AUTOSAR XML (schema 4-0-2)
package /AUTOSAR_ComM/SwcImplementations
  swc implementation ComM_Imp: programming-language=C, sw-version=5.4.0, vendor-id=6, behavior=ComM_Int
    code-descriptors:
      code ComM_Imp_Code: artifact-descriptors=autosar-engineering-object={short-label=Code, category=SWSRC}
    resource consumption ResourceConsumption_ResourceConsumption
package /AUTOSAR_ComM/SwComponentTypes
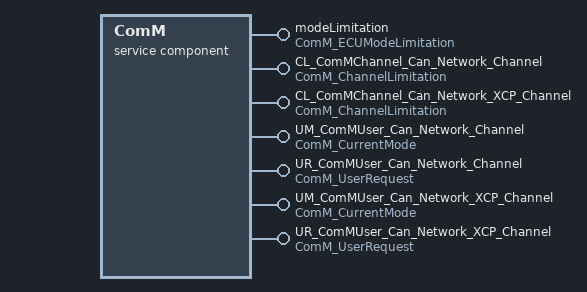
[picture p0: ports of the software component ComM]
  service sw component type ComM
    7 x provide port:
      modeLimitation: provided-interface=ComM_ECUModeLimitation
      CL_ComMChannel_Can_Network_Channel: provided-interface=ComM_ChannelLimitation
      CL_ComMChannel_Can_Network_XCP_Channel: provided-interface=ComM_ChannelLimitation
      UM_ComMUser_Can_Network_Channel: mode-switch-sender-com-spec{mode-group=currentMode, queue-length=1}, provided-interface=ComM_CurrentMode
      UR_ComMUser_Can_Network_Channel: server-com-spec{operation=RequestComMode, queue-length=5}, provided-interface=ComM_UserRequest
      UM_ComMUser_Can_Network_XCP_Channel: mode-switch-sender-com-spec{mode-group=currentMode, queue-length=1}, provided-interface=ComM_CurrentMode
      UR_ComMUser_Can_Network_XCP_Channel: server-com-spec{operation=RequestComMode, queue-length=5}, provided-interface=ComM_UserRequest
    behavior ComM_Int: data-type-mapping=ComMModeMapping, handle-termination-and-restart=CAN-BE-TERMINATED-AND-RESTARTED
      16 x operation invoked event:
        OIE_UR_ComMUser_Can_Network_Channel_RequestComMode: start-on-event=RequestComMode, operation=UR_ComMUser_Can_Network_Channel.RequestComMode
        OIE_UR_ComMUser_Can_Network_Channel_GetRequestedComMode: start-on-event=GetRequestedComMode, operation=UR_ComMUser_Can_Network_Channel.GetRequestedComMode
        OIE_UR_ComMUser_Can_Network_Channel_GetCurrentComMode: start-on-event=GetCurrentComMode, operation=UR_ComMUser_Can_Network_Channel.GetCurrentComMode
        OIE_UR_ComMUser_Can_Network_Channel_GetMaxComMode: start-on-event=GetMaxComMode, operation=UR_ComMUser_Can_Network_Channel.GetMaxComMode
        OIE_UR_ComMUser_Can_Network_XCP_Channel_RequestComMode: start-on-event=RequestComMode, operation=UR_ComMUser_Can_Network_XCP_Channel.RequestComMode
        OIE_UR_ComMUser_Can_Network_XCP_Channel_GetRequestedComMode: start-on-event=GetRequestedComMode, operation=UR_ComMUser_Can_Network_XCP_Channel.GetRequestedComMode
        OIE_UR_ComMUser_Can_Network_XCP_Channel_GetCurrentComMode: start-on-event=GetCurrentComMode, operation=UR_ComMUser_Can_Network_XCP_Channel.GetCurrentComMode
        OIE_UR_ComMUser_Can_Network_XCP_Channel_GetMaxComMode: start-on-event=GetMaxComMode, operation=UR_ComMUser_Can_Network_XCP_Channel.GetMaxComMode
        OIE_ML_LimitECUToNoComMode: start-on-event=LimitECUToNoComMode, operation=modeLimitation.LimitECUToNoComMode
        OIE_ML_ReadInhibitCounter: start-on-event=ReadInhibitCounter, operation=modeLimitation.ReadInhibitCounter
        OIE_ML_ResetInhibitCounter: start-on-event=ResetInhibitCounter, operation=modeLimitation.ResetInhibitCounter
        OIE_ML_SetECUGroupClassification: start-on-event=SetECUGroupClassification, operation=modeLimitation.SetECUGroupClassification
        OIE_CL_ComMChannel_Can_Network_Channel_LimitChannelToNoComMode: start-on-event=LimitChannelToNoComMode, operation=CL_ComMChannel_Can_Network_Channel.LimitChannelToNoComMode
        OIE_CL_ComMChannel_Can_Network_Channel_GetInhibitionStatus: start-on-event=GetInhibitionStatus, operation=CL_ComMChannel_Can_Network_Channel.GetInhibitionStatus
        OIE_CL_ComMChannel_Can_Network_XCP_Channel_LimitChannelToNoComMode: start-on-event=LimitChannelToNoComMode, operation=CL_ComMChannel_Can_Network_XCP_Channel.LimitChannelToNoComMode
        OIE_CL_ComMChannel_Can_Network_XCP_Channel_GetInhibitionStatus: start-on-event=GetInhibitionStatus, operation=CL_ComMChannel_Can_Network_XCP_Channel.GetInhibitionStatus
      port-api-options:
        {enable-take-address=false, indirect-api=false, port-defined-argument-value{value=UR_ComMUser_Can_Network_Channel:0, value-type=ComM_UserHandleType}, port=UR_ComMUser_Can_Network_Channel}
        {enable-take-address=false, indirect-api=false, port-defined-argument-value{value=UR_ComMUser_Can_Network_XCP_Channel:1, value-type=ComM_UserHandleType}, port=UR_ComMUser_Can_Network_XCP_Channel}
        {enable-take-address=false, indirect-api=false, port-defined-argument-value{value=CL_ComMChannel_Can_Network_Channel:0, value-type=NetworkHandleType}, port=CL_ComMChannel_Can_Network_Channel}
        {enable-take-address=false, indirect-api=false, port-defined-argument-value{value=CL_ComMChannel_Can_Network_XCP_Channel:1, value-type=NetworkHandleType}, port=CL_ComMChannel_Can_Network_XCP_Channel}
      12 x runnable:
        LimitECUToNoComMode: symbol=ComM_LimitECUToNoComMode
        ReadInhibitCounter: symbol=ComM_ReadInhibitCounter
        ResetInhibitCounter: symbol=ComM_ResetInhibitCounter
        SetECUGroupClassification: symbol=ComM_SetECUGroupClassification
        LimitChannelToNoComMode: symbol=ComM_LimitChannelToNoComMode
        GetInhibitionStatus: symbol=ComM_GetInhibitionStatus
        RequestComMode: symbol=ComM_RequestComMode
        MainFunction_ComMChannel_Can_Network_Channel: can-be-invoked-concurrently=true, symbol=ComM_MainFunction_ComMChannel_Can_Network_Channel
        MainFunction_ComMChannel_Can_Network_XCP_Channel: can-be-invoked-concurrently=true, symbol=ComM_MainFunction_ComMChannel_Can_Network_XCP_Channel
        GetMaxComMode: can-be-invoked-concurrently=true, symbol=ComM_GetMaxComMode
        GetRequestedComMode: can-be-invoked-concurrently=true, symbol=ComM_GetRequestedComMode
        GetCurrentComMode: can-be-invoked-concurrently=true, symbol=ComM_GetCurrentComMode
          mode switch point MSP_ComM_User_ComMUser_Can_Network_Channel: mode-group=UM_ComMUser_Can_Network_Channel.currentMode
          mode switch point MSP_ComM_User_ComMUser_Can_Network_XCP_Channel: mode-group=UM_ComMUser_Can_Network_XCP_Channel.currentMode
package /AUTOSAR_ComM/SwcBswMappings/SwcBswmapping
  swc bsw mapping SwcBswMapping_ComM: bsw-behavior=BswInternalBehavior, swc-behavior=ComM_Int
    runnable-mappings:
      bsw-entity=BSWSE_MainFunction_ComMChannel_Can_Network_Channel, swc-runnable=MainFunction_ComMChannel_Can_Network_Channel
      bsw-entity=BSWSE_MainFunction_ComMChannel_Can_Network_XCP_Channel, swc-runnable=MainFunction_ComMChannel_Can_Network_XCP_Channel
